# NANO112AN_v1 register map
File version: 1.0
Registers are 32-bit, read-write, reset 0x0 unless marked. A register's access mark holds for its fields unless they carry their own. Offsets are from the block's base; [hi:lo] are bit positions; {n}, {i} and the like mark numbered series; 'fields as' and 'values as' point back to an identical list.

## GP — GP Register Map
Base 0x50004000
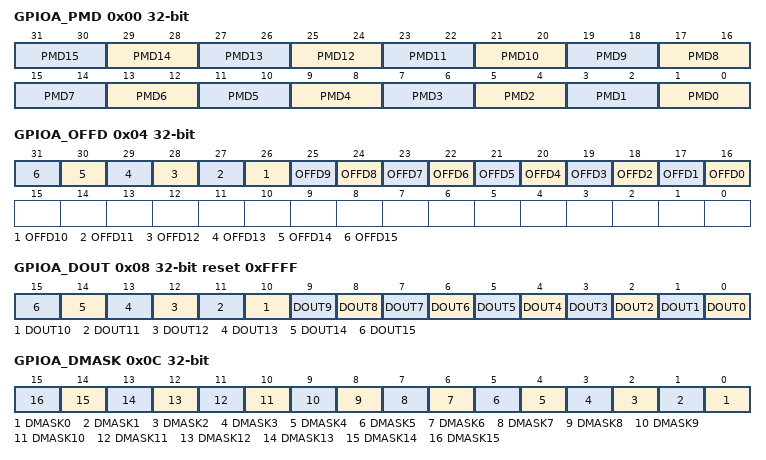
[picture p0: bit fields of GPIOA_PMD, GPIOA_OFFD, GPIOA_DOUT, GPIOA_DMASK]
0x00 GPIOA_PMD — GPIO Port A Pin I/O Mode Control Register
  [all] fields
    0=GPIO port [x] pin [n] is in INPUT mode; 1=GPIO port [x] pin [n] is in OUTPUT mode; 2=GPIO port [x] pin [n] is in Open-Drain mode
  [2n+1:2n] PMD{n} (n=0..15) — GPIO Port [X] Pin [N] Mode Control. Determine the I/O type of GPIO port [x] pin [n]. Note: For GPIOE_PMD, PMD10 ~ PMD15 are reserved. For GPIOF_PMD, PMD6 ~ PMD15 are reserved.
0x04 GPIOA_OFFD — GPIO Port A Pin OFF Digital Enable Register
  [all] fields
    0=Digital input path of GPIO port [x] pin [n] Enabled; 1=Digital input path of GPIO port [x] pin [n] Disabled (tied digital input to low)
  [n+16] OFFD{n} (n=0..15) — GPIO Port [X] Pin [N] Digital Input Path Disable. Determine if the digital input path of GPIO port [x] pin [n] is disabled. Note: For GPIOE_OFFD, bits [31:26] are reserved. For GPIOF_OFFD, bits [31:22] are reserved.
0x08 GPIOA_DOUT reset 0xFFFF — GPIO Port A Data Output Value Register
  [all] fields
    0=GPIO port [x] Pin [n] will drive Low if the corresponding output mode enabling bit is set; 1=GPIO port [x] Pin [n] will drive High if the corresponding output mode enabling bit is set
  [n] DOUT{n} (n=0..15) — GPIO Port [X] Pin [N] Output Value. Each of these bits controls the status of a GPIO port [x] pin [n] when the GPI/O pin is configures as output or open-drain mode. Note: For GPIOE_DOUT, bits [15:10] are reserved. For GPIOF_DOUT, bits [15:6] are reserved.
0x0C GPIOA_DMASK — GPIO Port A Data Output Write Mask Register
  [all] fields
    0=The corresponding GPIO_DOUT bit [n] can be updated; 1=The corresponding GPIO_DOUT bit [n] is protected
  [n] DMASK{n} (n=0..15) — GPIO Port [X] Pin [N] Data Output Write Mask. These bits are used to protect the corresponding register of GPIOx_DOUT bit [n]. When set the DMASK[n] to "1", the corresponding DOUT[n] bit is protected. The write signal is masked, write data to the protect bit is ignored. Note: For GPIOF_DMASK, bits [15:6] are reserved. Note: These mask bits only take effect while CPU is doing write operation to register GPIOx_DOUT. If CPU is doing write operation to register GPIO[x][n], these mask bits will not take effect.
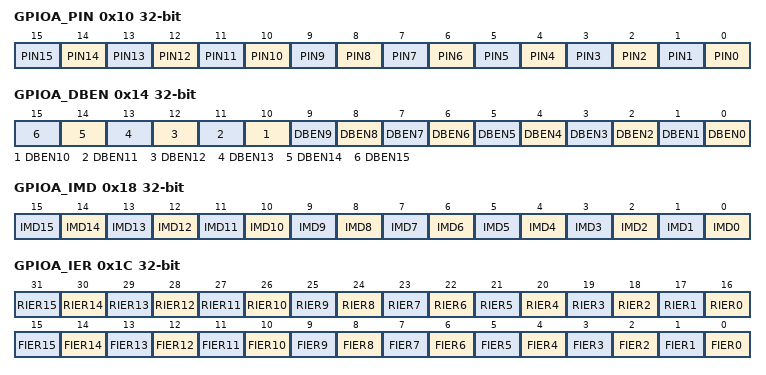
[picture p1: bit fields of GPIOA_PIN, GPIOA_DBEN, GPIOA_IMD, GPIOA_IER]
0x10 GPIOA_PIN ro (reset mask 0xFFFF0000) — GPIO Port A Pin Value Register
  [n] PIN{n} (n=0..15) — GPIO Port [X] Pin [N] Value. The value read from each of these bit reflects the actual status of the respective GPI/O pin. Note: For GPIOE_PIN, bits [15:10] are reserved. For GPIOF_PIN, bits [15:6] are reserved.
0x14 GPIOA_DBEN — GPIO Port A De-bounce Enable Register
  [all] fields
    0=The GPIO port [x] Pin [n] input signal de-bounce function Disabled; 1=The GPIO port [x] Pin [n] input signal de-bounce function Enabled
  [n] DBEN{n} (n=0..15) — GPIO Port [X] Pin [N] Input Signal De-bounce Enable Control. DBEN[n] used to enable the de-bounce function for each corresponding bit. If the input signal pulse width cannot be sampled by continuous two de-bounce sample cycle the input signal transition is seen as the signal bounce and will not trigger the interrupt. DBEN[n] is used for "edge-trigger" interrupt only, and ignored for "level trigger" interrupt. The de-bounce function is valid for edge triggered interrupt. If the interrupt mode is level triggered, the de-bounce enable bit is ignored. Note: For GPIOE_DBEN, bits [15:10] are reserved. For GPIOF_DBEN, bits [15:6] are reserved.
0x18 GPIOA_IMD — GPIO Port A Interrupt Mode Control Register
  [all] fields
    0=Edge trigger interrupt; 1=Level trigger interrupt
  [n] IMD{n} (n=0..15) — GPIO Port [X] Pin [N] Edge or Level Detection Interrupt Control. IMD[n] used to control the interrupt is by level trigger or by edge trigger. If the interrupt is by edge trigger, the trigger source is control de-bounce. If the interrupt is by level trigger, the input source is sampled by one clock and the generate the interrupt. If set pin as the level trigger interrupt, then only one level can be set on the registers GPIOX_IER. If set both the level to trigger interrupt, the setting is ignored and no interrupt will occur. The de-bounce function is valid for edge triggered interrupt. If the interrupt mode is level triggered, the de-bounce enable bit is ignored. Note: For GPIOE_IMD, bits [15:10] are reserved. For GPIOF_IMD, bits [15:6] are reserved.
0x1C GPIOA_IER — GPIO Port A Interrupt Enable Register
  [n+16] RIER{n} (n=0..15) — GPIO Port [X] Pin [N] Interrupt Enable by Input Rising Edge or Input Level High. RIER[x] used to enable the interrupt for each of the corresponding input GPIO_PIN[x]. Set bit "1" also enable the pin wake-up function. When set the RIER[x] bit "1": If the interrupt is level mode trigger, the input PIN[x] state at level "high" will generate the interrupt. If the interrupt is edge mode trigger, the input PIN[x] state change from "low-to-high" will generate the interrupt. Note: For GPIOE_IE, bits [31:26] are reserved. For GPIOF_IE, bits [31:22] are reserved.
    0=PIN[x] level-high or low-to-high interrupt Disabled; 1=PIN[x] level-high or low-to-high interrupt Enabled
  [n] FIER{n} (n=0..15) — GPIO Port [X] Pin [N] Interrupt Enable by Input Falling Edge or Input Level Low. FIER[n] used to enable the interrupt for each of the corresponding input GPIO_PIN[n]. Set bit "1" also enable the pin wake-up function. When set the FIER[n] bit "1": If the interrupt is level mode trigger, the input PIN[n] state at level "low" will generate the interrupt. If the interrupt is edge mode trigger, the input PIN[n] state change from "high-to-low" will generate the interrupt. Note: For GPIOE_IER, bits [15:10] are reserved. For GPIOF_IER, bits [15:6] are reserved.
    0=PIN[n] state low-level or high-to-low change interrupt Disabled; 1=PIN[n] state low-level or high-to-low change interrupt Enabled
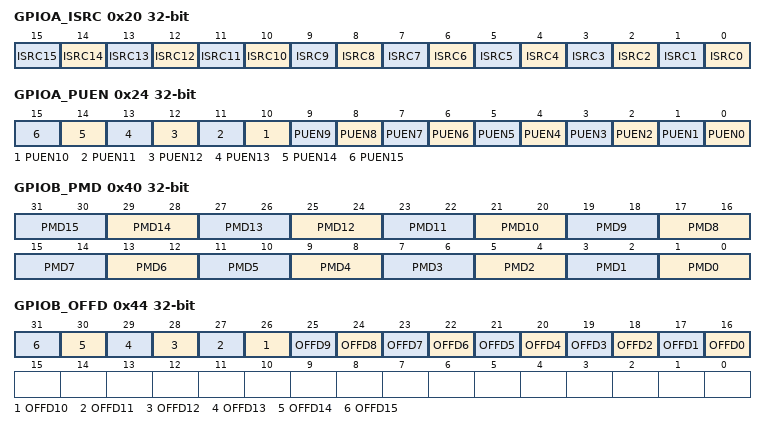
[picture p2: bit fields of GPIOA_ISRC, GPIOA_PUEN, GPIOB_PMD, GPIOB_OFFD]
0x20 GPIOA_ISRC reset not defined — GPIO Port A Interrupt Trigger Source Status Register
  [all] fields
    0=No interrupt at Port x[n]. No action; 1=Port x[n] generate an interrupt. Clear the correspond pending interrupt
  [n] ISRC{n} (n=0..15) — GPIO Port [X] Pin [N] Interrupt Trigger Source Indicator. Read Operation: Note: For GPIOE_ISRC, bits [15:10] are reserved. For GPIOF_ISRC, bits [15:6] are reserved.
0x24 GPIOA_PUEN — GPIO Port A Pull-up Enable Register
  [all] fields
    0=GPIO port [A/B/C/D/E/F] bit [n] pull-up resistor Disabled; 1=GPIO port [A/B/C/D/E/F] bit [n] pull-up resistor Enabled
  [n] PUEN{n} (n=0..15) — GPIO Port [X] Pin [N] Pull-up Enable Register. Read Operation: . Note: For GPIOE_PUEN, bits [15:10] are reserved. For GPIOF_PUEN, bits [15:6] are reserved.
0x40 GPIOB_PMD — GPIO Port B Pin I/O Mode Control Register
  fields as GPIOA_PMD
0x44 GPIOB_OFFD — GPIO Port B Pin OFF Digital Enable Register
  fields as GPIOA_OFFD
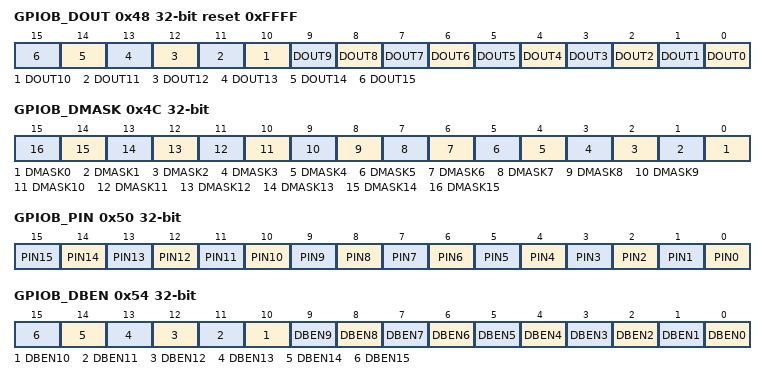
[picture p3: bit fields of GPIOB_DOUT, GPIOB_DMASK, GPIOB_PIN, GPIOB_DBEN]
0x48 GPIOB_DOUT reset 0xFFFF — GPIO Port B Data Output Value Register
  fields as GPIOA_DOUT
0x4C GPIOB_DMASK — GPIO Port B Data Output Write Mask Register
  fields as GPIOA_DMASK
0x50 GPIOB_PIN ro (reset mask 0xFFFF0000) — GPIO Port B Pin Value Register
  fields as GPIOA_PIN
0x54 GPIOB_DBEN — GPIO Port B De-bounce Enable Register
  fields as GPIOA_DBEN
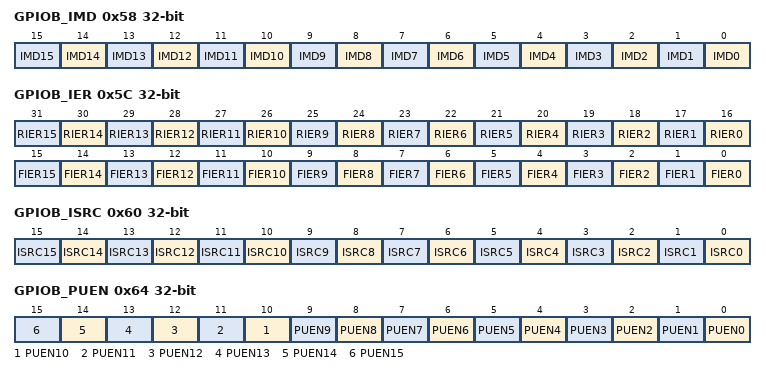
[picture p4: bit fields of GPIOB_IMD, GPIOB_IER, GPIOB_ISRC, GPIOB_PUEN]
0x58 GPIOB_IMD — GPIO Port B Interrupt Mode Control Register
  fields as GPIOA_IMD
0x5C GPIOB_IER — GPIO Port B Interrupt Enable Register
  fields as GPIOA_IER
0x60 GPIOB_ISRC reset not defined — GPIO Port B Interrupt Trigger Source Status Register
  fields as GPIOA_ISRC
0x64 GPIOB_PUEN — GPIO Port B Pull-up Enable Register
  fields as GPIOA_PUEN
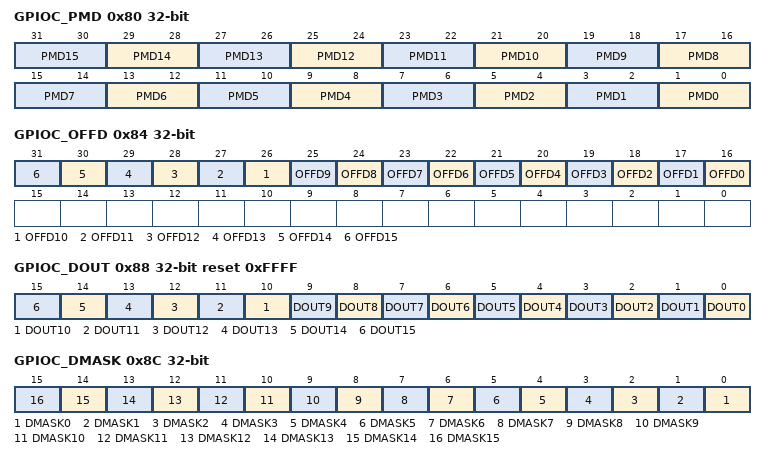
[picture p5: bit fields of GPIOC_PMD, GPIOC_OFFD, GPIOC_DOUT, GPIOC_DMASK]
0x80 GPIOC_PMD — GPIO Port C Pin I/O Mode Control Register
  fields as GPIOA_PMD
0x84 GPIOC_OFFD — GPIO Port C Pin OFF Digital Enable Register
  fields as GPIOA_OFFD
0x88 GPIOC_DOUT reset 0xFFFF — GPIO Port C Data Output Value Register
  fields as GPIOA_DOUT
0x8C GPIOC_DMASK — GPIO Port C Data Output Write Mask Register
  fields as GPIOA_DMASK
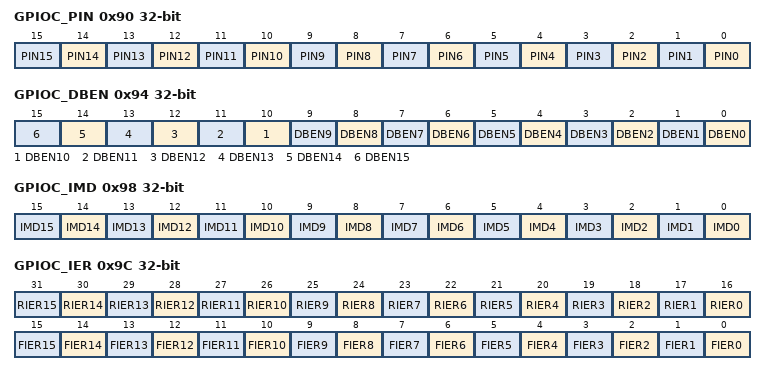
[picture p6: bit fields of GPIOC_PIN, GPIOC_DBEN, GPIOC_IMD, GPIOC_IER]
0x90 GPIOC_PIN ro (reset mask 0xFFFF0000) — GPIO Port C Pin Value Register
  fields as GPIOA_PIN
0x94 GPIOC_DBEN — GPIO Port C De-bounce Enable Register
  fields as GPIOA_DBEN
0x98 GPIOC_IMD — GPIO Port C Interrupt Mode Control Register
  fields as GPIOA_IMD
0x9C GPIOC_IER — GPIO Port C Interrupt Enable Register
  fields as GPIOA_IER
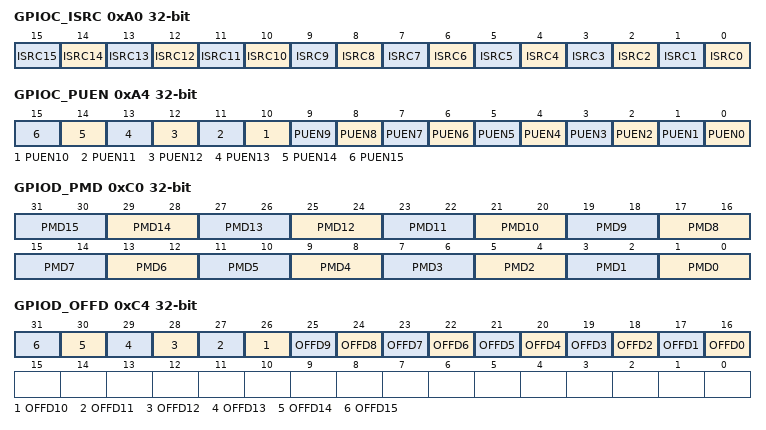
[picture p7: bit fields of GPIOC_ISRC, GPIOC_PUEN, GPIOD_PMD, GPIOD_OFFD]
0xA0 GPIOC_ISRC reset not defined — GPIO Port C Interrupt Trigger Source Status Register
  fields as GPIOA_ISRC
0xA4 GPIOC_PUEN — GPIO Port C Pull-up Enable Register
  fields as GPIOA_PUEN
0xC0 GPIOD_PMD — GPIO Port D Pin I/O Mode Control Register
  fields as GPIOA_PMD
0xC4 GPIOD_OFFD — GPIO Port D Pin OFF Digital Enable Register
  fields as GPIOA_OFFD
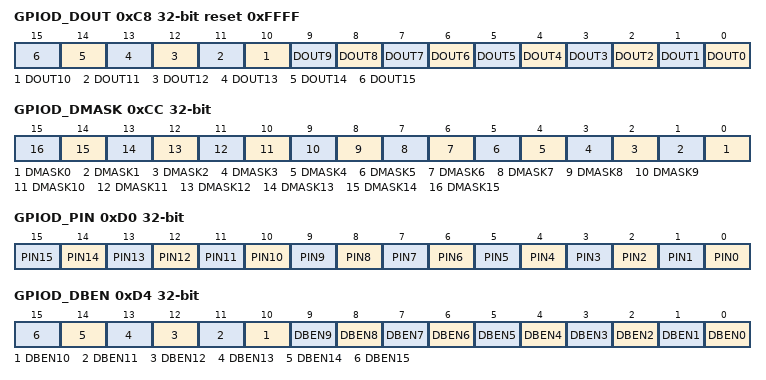
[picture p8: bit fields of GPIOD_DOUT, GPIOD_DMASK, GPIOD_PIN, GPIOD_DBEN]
0xC8 GPIOD_DOUT reset 0xFFFF — GPIO Port D Data Output Value Register
  fields as GPIOA_DOUT
0xCC GPIOD_DMASK — GPIO Port D Data Output Write Mask Register
  fields as GPIOA_DMASK
0xD0 GPIOD_PIN ro (reset mask 0xFFFF0000) — GPIO Port D Pin Value Register
  fields as GPIOA_PIN
0xD4 GPIOD_DBEN — GPIO Port D De-bounce Enable Register
  fields as GPIOA_DBEN
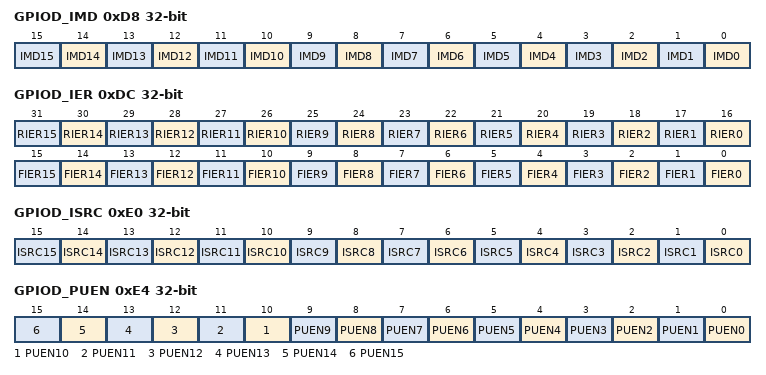
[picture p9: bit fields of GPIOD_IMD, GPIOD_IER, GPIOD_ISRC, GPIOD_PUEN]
0xD8 GPIOD_IMD — GPIO Port D Interrupt Mode Control Register
  fields as GPIOA_IMD
0xDC GPIOD_IER — GPIO Port D Interrupt Enable Register
  fields as GPIOA_IER
0xE0 GPIOD_ISRC reset not defined — GPIO Port D Interrupt Trigger Source Status Register
  fields as GPIOA_ISRC
0xE4 GPIOD_PUEN — GPIO Port D Pull-up Enable Register
  fields as GPIOA_PUEN
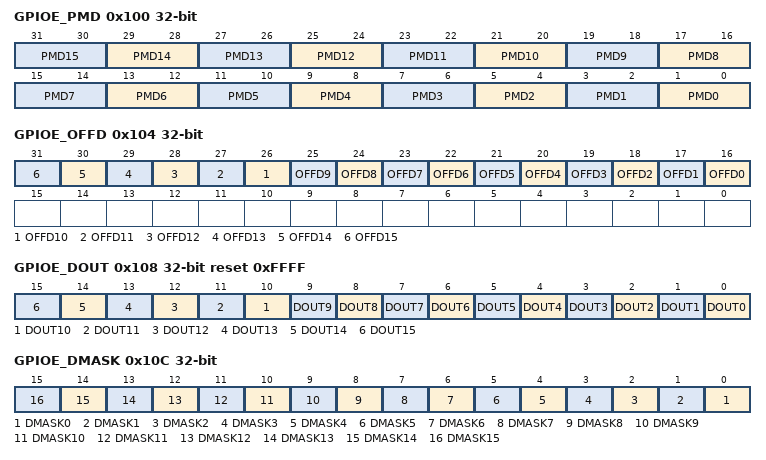
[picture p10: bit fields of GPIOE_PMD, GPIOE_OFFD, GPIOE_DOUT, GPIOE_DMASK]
0x100 GPIOE_PMD — GPIO Port E Pin I/O Mode Control Register
  fields as GPIOA_PMD
0x104 GPIOE_OFFD — GPIO Port E Pin OFF Digital Enable Register
  fields as GPIOA_OFFD
0x108 GPIOE_DOUT reset 0xFFFF — GPIO Port E Data Output Value Register
  fields as GPIOA_DOUT
0x10C GPIOE_DMASK — GPIO Port E Data Output Write Mask Register
  fields as GPIOA_DMASK
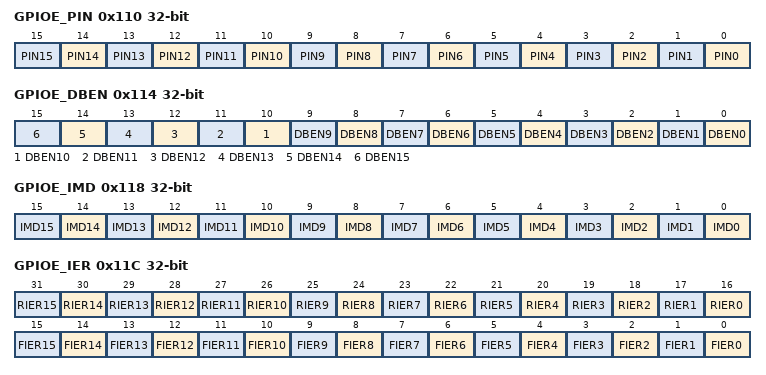
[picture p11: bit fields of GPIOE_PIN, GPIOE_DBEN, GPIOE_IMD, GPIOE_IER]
0x110 GPIOE_PIN ro (reset mask 0xFFFF0000) — GPIO Port E Pin Value Register
  fields as GPIOA_PIN
0x114 GPIOE_DBEN — GPIO Port E De-bounce Enable Register
  fields as GPIOA_DBEN
0x118 GPIOE_IMD — GPIO Port E Interrupt Mode Control Register
  fields as GPIOA_IMD
0x11C GPIOE_IER — GPIO Port E Interrupt Enable Register
  fields as GPIOA_IER
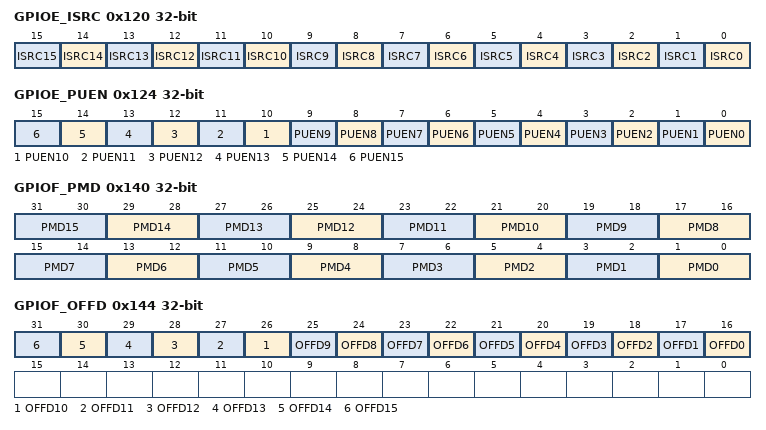
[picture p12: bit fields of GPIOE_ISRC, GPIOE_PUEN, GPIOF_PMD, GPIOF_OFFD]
0x120 GPIOE_ISRC reset not defined — GPIO Port E Interrupt Trigger Source Status Register
  fields as GPIOA_ISRC
0x124 GPIOE_PUEN — GPIO Port E Pull-up Enable Register
  fields as GPIOA_PUEN
0x140 GPIOF_PMD — GPIO Port F Pin I/O Mode Control Register
  fields as GPIOA_PMD
0x144 GPIOF_OFFD — GPIO Port F Pin OFF Digital Enable Register
  fields as GPIOA_OFFD
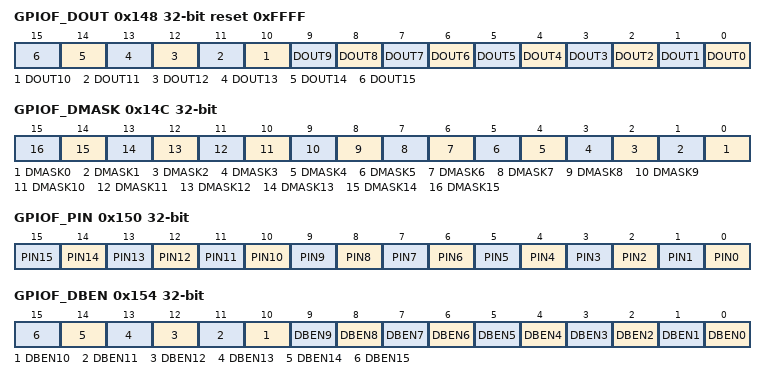
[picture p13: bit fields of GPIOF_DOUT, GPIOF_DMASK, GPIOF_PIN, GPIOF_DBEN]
0x148 GPIOF_DOUT reset 0xFFFF — GPIO Port F Data Output Value Register
  fields as GPIOA_DOUT
0x14C GPIOF_DMASK — GPIO Port F Data Output Write Mask Register
  fields as GPIOA_DMASK
0x150 GPIOF_PIN ro (reset mask 0xFFFF0000) — GPIO Port F Pin Value Register
  fields as GPIOA_PIN
0x154 GPIOF_DBEN — GPIO Port F De-bounce Enable Register
  fields as GPIOA_DBEN
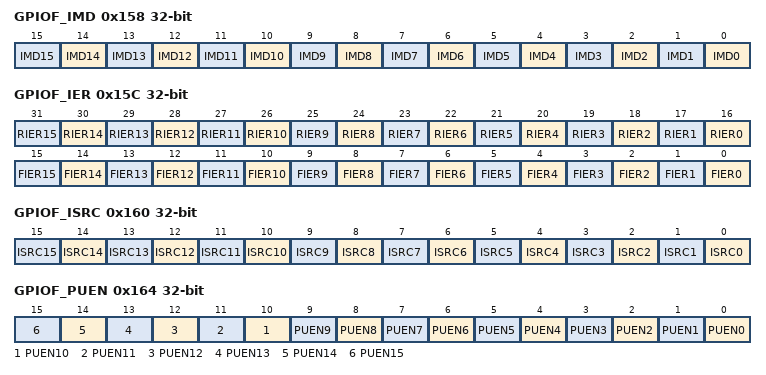
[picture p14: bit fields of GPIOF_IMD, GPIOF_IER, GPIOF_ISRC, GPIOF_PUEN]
0x158 GPIOF_IMD — GPIO Port F Interrupt Mode Control Register
  fields as GPIOA_IMD
0x15C GPIOF_IER — GPIO Port F Interrupt Enable Register
  fields as GPIOA_IER
0x160 GPIOF_ISRC reset not defined — GPIO Port F Interrupt Trigger Source Status Register
  fields as GPIOA_ISRC
0x164 GPIOF_PUEN — GPIO Port F Pull-up Enable Register
  fields as GPIOA_PUEN
0x180 DBNCECON — De-bounce Cycle Control Register
  [5] DBCLK_ON — De-bounce Clock Enable Control. This bit controls if the de-bounce clock is enabled. However, if GPI/O pin's interrupt is enabled, the de-bounce clock will be enabled automatically no matter what the DBCLK_ON value is. If CPU is in sleep mode, this bit didn't take effect. And only the GPI/O pin with interrupt enable could get de-bounce clock.
    0=De-bounce clock Disabled; 1=De-bounce clock Enabled
  [4] DBCLKSRC — De-bounce Counter Clock Source Selection
    0=De-bounce counter Clock Source is the HCLK; 1=De-bounce counter Clock Source is the internal 10 kHz clock
  [3:0] DBCLKSEL — De-bounce Sampling Cycle Selection
    0=Sample interrupt input once per 1 clock; 1=Sample interrupt input once per 2 clocks; 2=Sample interrupt input once per 4 clocks; 3=Sample interrupt input once per 8 clocks; 4=Sample interrupt input once per 16 clocks; 5=Sample interrupt input once per 32 clocks; 6=Sample interrupt input once per 64 clocks; 7=Sample interrupt input once per 128 clocks; 8=Sample interrupt input once per 256 clocks; 9=Sample interrupt input once per 2*256 clocks; 10=Sample interrupt input once per 4*256clocks; 11=Sample interrupt input once per 8*256 clocks; 12=Sample interrupt input once per 16*256 clocks; 13=Sample interrupt input once per 32*256 clocks; 14=Sample interrupt input once per 64*256 clocks; 15=Sample interrupt input once per 128*256 clocks
{0x200+4i} GPIOA{i} (reset mask 0xFFFFFFF0) (i=0..15) — GPIO Port A Bit {i} Data Register
  [0] GPIO — GPIO Port [X] Pin [N] I/O Data. This field supports the bit operation mode on related GPIO port [x] pin [n]. Writing this filed to set the corresponding GPIO port [x] pin [n] output value while reading this field to get the corresponding GPIO port [x] pin [n] value. Read Operation: . Note: The write operation will not be affected by register GPIOx_DMASK.
    0=The corresponding GPIO port [x] pin [n] value is low. Set corresponding GPIO port [x] pin [n] to low; 1=The corresponding GPIO port [x] pin [n] value is high. Set corresponding GPIO port [x] pin [n] to high
{0x240+4i} GPIOB{i} (reset mask 0xFFFFFFF0) (i=0..15) — GPIO Port B Bit {i} Data Register
  fields as GPIOA0
{0x280+4i} GPIOC{i} (reset mask 0xFFFFFFF0) (i=0..15) — GPIO Port C Bit {i} Data Register
  fields as GPIOA0
{0x2C0+4i} GPIOD{i} (reset mask 0xFFFFFFF0) (i=0..15) — GPIO Port D Bit {i} Data Register
  fields as GPIOA0
{0x300+4i} GPIOE{i} (reset mask 0xFFFFFFF0) (i=0..9) — GPIO Port E Bit {i} Data Register
  fields as GPIOA0
{0x340+4i} GPIOF{i} (reset mask 0xFFFFFFF0) (i=0..5) — GPIO Port F Bit {i} Data Register
  fields as GPIOA0
